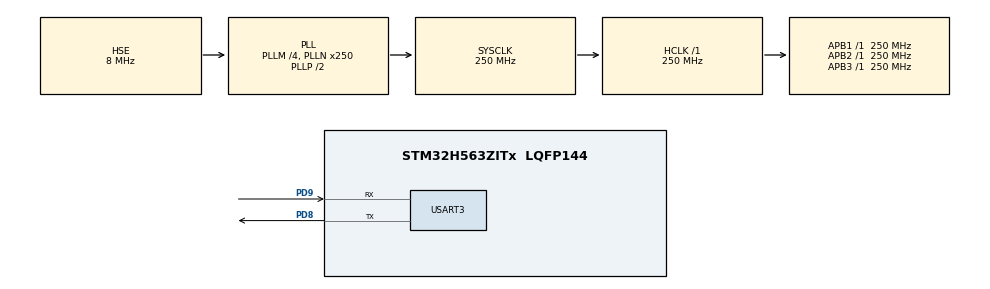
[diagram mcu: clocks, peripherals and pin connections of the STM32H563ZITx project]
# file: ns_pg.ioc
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BOOTPATH.BootPathName=LEGACY
BOOTPATH.UserSelectedBootPath=LEGACY
CORTEX_M33_NS.Number-Cortex_Memory_Protection_Unit_Region0_OTP_RO_AREAS_Settings=MPU_REGION_NUMBER0
CORTEX_M33_NS.default_mode_Activation=1
CORTEX_M33_NS.userName=CORTEX_M33
Mcu.Family=STM32H5
Mcu.Name=STM32H563ZITx
Mcu.Package=LQFP144
NVIC.PriorityGroup=NVIC_PRIORITYGROUP_4
PA13(JTMS/SWDIO).GPIO_Label=SWDIO
PA13(JTMS/SWDIO).Mode=Serial_Wire
PA13(JTMS/SWDIO).Signal=DEBUG_JTMS-SWDIO
PA14(JTCK/SWCLK).GPIO_Label=SWCLK
PA14(JTCK/SWCLK).Mode=Serial_Wire
PA14(JTCK/SWCLK).Signal=DEBUG_JTCK-SWCLK
PC14-OSC32_IN(OSC32_IN).Mode=LSE-External-Oscillator
PC14-OSC32_IN(OSC32_IN).Signal=RCC_OSC32_IN
PC15-OSC32_OUT(OSC32_OUT).Mode=LSE-External-Oscillator
PC15-OSC32_OUT(OSC32_OUT).Signal=RCC_OSC32_OUT
PD8.Mode=Asynchronous
PD8.Signal=USART3_TX
PD9.Mode=Asynchronous
PD9.Signal=USART3_RX
PH0-OSC_IN(PH0).GPIO_Label=STLK_MCO
PH0-OSC_IN(PH0).Mode=HSE-External-Clock-Source
PH0-OSC_IN(PH0).Signal=RCC_OSC_IN
ProjectManager.HeapSize=0x200
ProjectManager.StackSize=0x400
ProjectManager.TargetToolchain=CMake
RCC.ADCFreq_Value=250000000
RCC.AHBFreq_Value=250000000
RCC.APB1Freq_Value=250000000
RCC.APB1TimFreq_Value=250000000
RCC.APB2Freq_Value=250000000
RCC.APB2TimFreq_Value=250000000
RCC.APB3Freq_Value=250000000
RCC.CSI_VALUE=4000000
RCC.CortexFreq_Value=250000000
RCC.EPOD_VALUE=8000000
RCC.HCLKFreq_Value=250000000
RCC.HSE_VALUE=8000000
RCC.HSI48_VALUE=48000000
RCC.HSIDiv=RCC_HSI_DIV1
RCC.HSI_VALUE=64000000
RCC.LSIRC_VALUE=32000
RCC.PLLM=4
RCC.PLLN=250
RCC.PLLSourceVirtual=RCC_PLL1_SOURCE_HSE
RCC.SYSCLKFreq_VALUE=250000000
RCC.SYSCLKSource=RCC_SYSCLKSOURCE_PLLCLK
RCC.USBFreq_Value=48000000
RCC.VCOOutputFreq_Value=500000000
USART3.VirtualMode-Asynchronous=VM_ASYNC
VP_BOOTPATH_VS_BOOTPATH.Mode=BP_Activate
VP_CORTEX_M33_NS_VS_Hclk.Mode=Hclk_Mode
VP_ICACHE_VS_ICACHE.Mode=DirectMappedCache
VP_MEMORYMAP_VS_MEMORYMAP.Mode=CurAppReg
VP_PWR_VS_DBSignals.Mode=DisableDeadBatterySignals
VP_PWR_VS_LPOM.Mode=PowerOptimisation
VP_PWR_VS_SECSignals.Mode=Security/Privilege
board=NUCLEO-H563ZI

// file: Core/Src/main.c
/* USER CODE BEGIN Header */
/**
 ******************************************************************************
 * @file           : main.c
 * @brief          : Main program body
 ******************************************************************************
 * @attention
 *
 * Copyright (c) 2026 STMicroelectronics.
 * All rights reserved.
 *
 * This software is licensed under terms that can be found in the LICENSE file
 * in the root directory of this software component.
 * If no LICENSE file comes with this software, it is provided AS-IS.
 *
 ******************************************************************************
 */
/* USER CODE END Header */
#include "main.h"
#include "gpio.h"
#include "icache.h"
#include "usart.h"

/* USER CODE BEGIN Includes */

#include "app.h"

/* USER CODE END Includes */

void SystemClock_Config(void);
static void MPU_Config(void);

int main(void) {

  /* MCU Configuration--------------------------------------------------------*/

  /* MPU Configuration--------------------------------------------------------*/
  MPU_Config();

  /* Reset of all peripherals, Initializes the Flash interface and the Systick.
   */
  HAL_Init();

  /* Configure the system clock */
  SystemClock_Config();

  /* Initialize all configured peripherals */
  MX_GPIO_Init();
  MX_ICACHE_Init();
  MX_USART3_UART_Init();
  /* USER CODE BEGIN 2 */
  app_entry();
  /* USER CODE END 2 */

  /* Infinite loop */
  while (1) {
  }
}

void SystemClock_Config(void) {
  RCC_OscInitTypeDef RCC_OscInitStruct = {0};
  RCC_ClkInitTypeDef RCC_ClkInitStruct = {0};

  /** Configure the main internal regulator output voltage
   */
  __HAL_PWR_VOLTAGESCALING_CONFIG(PWR_REGULATOR_VOLTAGE_SCALE0);

  while (!__HAL_PWR_GET_FLAG(PWR_FLAG_VOSRDY)) {
  }

  /** Initializes the RCC Oscillators according to the specified parameters
   * in the RCC_OscInitTypeDef structure.
   */
  RCC_OscInitStruct.OscillatorType = RCC_OSCILLATORTYPE_HSE;
  RCC_OscInitStruct.HSEState = RCC_HSE_BYPASS;
  RCC_OscInitStruct.PLL.PLLState = RCC_PLL_ON;
  RCC_OscInitStruct.PLL.PLLSource = RCC_PLL1_SOURCE_HSE;
  RCC_OscInitStruct.PLL.PLLM = 4;
  RCC_OscInitStruct.PLL.PLLN = 250;
  RCC_OscInitStruct.PLL.PLLP = 2;
  RCC_OscInitStruct.PLL.PLLQ = 2;
  RCC_OscInitStruct.PLL.PLLR = 2;
  RCC_OscInitStruct.PLL.PLLRGE = RCC_PLL1_VCIRANGE_1;
  RCC_OscInitStruct.PLL.PLLVCOSEL = RCC_PLL1_VCORANGE_WIDE;
  RCC_OscInitStruct.PLL.PLLFRACN = 0;
  if (HAL_RCC_OscConfig(&RCC_OscInitStruct) != HAL_OK) {
    Error_Handler();
  }

  /** Initializes the CPU, AHB and APB buses clocks
   */
  RCC_ClkInitStruct.ClockType = RCC_CLOCKTYPE_HCLK | RCC_CLOCKTYPE_SYSCLK |
                                RCC_CLOCKTYPE_PCLK1 | RCC_CLOCKTYPE_PCLK2 |
                                RCC_CLOCKTYPE_PCLK3;
  RCC_ClkInitStruct.SYSCLKSource = RCC_SYSCLKSOURCE_PLLCLK;
  RCC_ClkInitStruct.AHBCLKDivider = RCC_SYSCLK_DIV1;
  RCC_ClkInitStruct.APB1CLKDivider = RCC_HCLK_DIV1;
  RCC_ClkInitStruct.APB2CLKDivider = RCC_HCLK_DIV1;
  RCC_ClkInitStruct.APB3CLKDivider = RCC_HCLK_DIV1;

  if (HAL_RCC_ClockConfig(&RCC_ClkInitStruct, FLASH_LATENCY_5) != HAL_OK) {
    Error_Handler();
  }

  /** Configure the programming delay
   */
  __HAL_FLASH_SET_PROGRAM_DELAY(FLASH_PROGRAMMING_DELAY_2);
}

/* MPU Configuration */

void MPU_Config(void) {
  MPU_Region_InitTypeDef MPU_InitStruct = {0};
  MPU_Attributes_InitTypeDef MPU_AttributesInit = {0};

  /* Disables the MPU */
  HAL_MPU_Disable();

  /** Initializes and configures the Region 0 and the memory to be protected
   */
  MPU_InitStruct.Enable = MPU_REGION_ENABLE;
  MPU_InitStruct.Number = MPU_REGION_NUMBER0;
  MPU_InitStruct.BaseAddress = 0x08FFF000;
  MPU_InitStruct.LimitAddress = 0x08FFFFFF;
  MPU_InitStruct.AttributesIndex = MPU_ATTRIBUTES_NUMBER0;
  MPU_InitStruct.AccessPermission = MPU_REGION_ALL_RO;
  MPU_InitStruct.DisableExec = MPU_INSTRUCTION_ACCESS_DISABLE;
  MPU_InitStruct.IsShareable = MPU_ACCESS_NOT_SHAREABLE;

  HAL_MPU_ConfigRegion(&MPU_InitStruct);

  /** Initializes and configures the Attribute 0 and the memory to be protected
   */
  MPU_AttributesInit.Number = MPU_ATTRIBUTES_NUMBER0;
  MPU_AttributesInit.Attributes = INNER_OUTER(MPU_NOT_CACHEABLE);

  HAL_MPU_ConfigMemoryAttributes(&MPU_AttributesInit);
  /* Enables the MPU */
  HAL_MPU_Enable(MPU_PRIVILEGED_DEFAULT);
}

void Error_Handler(void) {
  __disable_irq();
  while (1) {
  }
}
#ifdef USE_FULL_ASSERT
/**
 * @brief  Reports the name of the source file and the source line number
 *         where the assert_param error has occurred.
 * @param  file: pointer to the source file name
 * @param  line: assert_param error line source number
 * @retval None
 */
void assert_failed(uint8_t *file, uint32_t line) {
  /* USER CODE BEGIN 6 */
  /* User can add his own implementation to report the file name and line
     number, ex: printf("Wrong parameters value: file %s on line %d\r\n", file,
     line) */
  /* USER CODE END 6 */
}
#endif /* USE_FULL_ASSERT */
